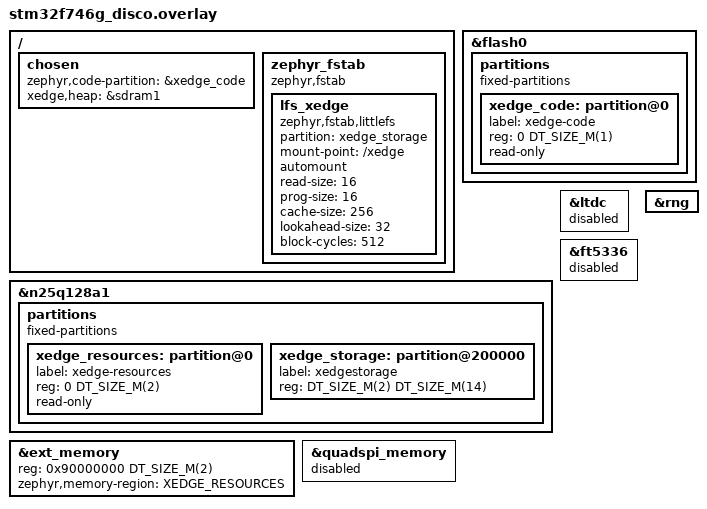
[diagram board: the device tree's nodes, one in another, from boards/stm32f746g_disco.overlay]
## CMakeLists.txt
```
cmake_minimum_required(VERSION 3.20.0)

# Find Zephyr package (this sets up the build system)
find_package(Zephyr REQUIRED HINTS $ENV{ZEPHYR_BASE})

project(XedgeInit)

# Application source files
target_sources(app PRIVATE src/main.c src/mdns.c)
include(${CMAKE_CURRENT_SOURCE_DIR}/../zephyr/Dns.cmake)

if(CONFIG_BOARD_FRDM_RW612 AND CONFIG_XEDGE_PSA)
  set_property(TARGET zephyr_property_target APPEND PROPERTY TFM_CMAKE_OPTIONS
    -DTFM_EXTRA_CONFIG_PATH=${CMAKE_CURRENT_SOURCE_DIR}/tfm/frdm_rw612/config.cmake)
  # Match the algorithms enabled by NXP's TF-M crypto configuration.
  zephyr_compile_definitions(
    SHARKSSL_USE_CHACHA20=0
    SHARKSSL_USE_POLY1305=0
    SHARKSSL_ECC_USE_BRAINPOOLP256R1=0
    SHARKSSL_ECC_USE_BRAINPOOLP384R1=0
    SHARKSSL_ECC_USE_BRAINPOOLP512R1=0
  )
endif()

if(CONFIG_FLASH_MCUX_FLEXSPI_XIP)
  # The controller addresses must remain readable while the XIP flash is busy.
  # Zephyr relocates this driver's code; also relocate its constant configuration.
  zephyr_code_relocate(
    FILES ${ZEPHYR_BASE}/drivers/memc/memc_mcux_flexspi.c
    LOCATION ${CONFIG_FLASH_MCUX_FLEXSPI_XIP_MEM}_RODATA
  )
endif()
```

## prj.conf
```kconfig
# Shared Xedge configuration. Hardware and simulator settings live in boards/.

# Enable Xedge module
CONFIG_XEDGE=y


# --- Sockets / contexts / FDs ---
# Each TCP connection consumes a net_context and a POSIX FD.
CONFIG_NET_MAX_CONTEXTS=32
CONFIG_NET_MAX_CONN=32
CONFIG_NET_SOCKETS_POLL_MAX=64

# --- Buffers (keep or increase from earlier tuning) ---
# Ensure pools don't starve when you scale connections.
CONFIG_NET_BUF_DATA_SIZE=512
CONFIG_NET_BUF_RX_COUNT=128
CONFIG_NET_BUF_TX_COUNT=128
CONFIG_NET_PKT_RX_COUNT=128
CONFIG_NET_PKT_TX_COUNT=128

# Bound each connection's window so concurrent IDE asset downloads share pools.
CONFIG_NET_TCP_MAX_SEND_WINDOW_SIZE=4096
CONFIG_NET_TCP_MAX_RECV_WINDOW_SIZE=4096

# --- Debug aids (temporarily) ---
CONFIG_LOG=y
CONFIG_LOG_DEFAULT_LEVEL=3
CONFIG_NET_LOG=y
CONFIG_NET_STATISTICS=y
CONFIG_NET_STATISTICS_USER_API=y


# Networking - Essential for HTTP server
CONFIG_NETWORKING=y
CONFIG_NET_IPV4=y
CONFIG_NET_IPV6=y
CONFIG_NET_TCP=y
CONFIG_NET_UDP=y
CONFIG_NET_SOCKETS=y
CONFIG_SNTP=y

# DNS resolver; each board selects static or DHCP-provided servers.
CONFIG_DNS_RESOLVER=y
# Keep the multicast entries added after DHCP initializes unicast DNS.
CONFIG_DNS_RECONFIGURE_CLEANUP=n
# Helpful if some domains have big/long answers
CONFIG_DNS_RESOLVER_ADDITIONAL_BUF_CTR=3
CONFIG_DNS_NUM_CONCUR_QUERIES=3
# Process DNS replies before the Xedge TLS workers (base priority 5).
# The default socket-service priority can starve until DNS queries time out.
CONFIG_NET_SOCKETS_SERVICE_THREAD_PRIO=2
# Native mDNS runs in this thread and needs more than the default 1400 bytes.
CONFIG_NET_SOCKETS_SERVICE_STACK_SIZE=4096

# Native mDNS on every target, including Lua-selected SharkCA hostnames.
CONFIG_MDNS_RESPONDER=y
CONFIG_MDNS_RESOLVER=y
CONFIG_NET_HOSTNAME_ENABLE=y
CONFIG_NET_HOSTNAME_DYNAMIC=y
CONFIG_NET_HOSTNAME_MAX_LEN=63
CONFIG_NET_HOSTNAME="xedge"
CONFIG_NET_HOSTNAME_UNIQUE=y

# Initialize the board's network interface before starting Xedge.
CONFIG_NET_CONFIG_AUTO_INIT=y
CONFIG_NET_CONFIG_SETTINGS=y
CONFIG_NET_CONFIG_NEED_IPV4=y


# Threading and scheduling
CONFIG_MULTITHREADING=y
CONFIG_NUM_PREEMPT_PRIORITIES=16
CONFIG_NUM_COOP_PRIORITIES=16
CONFIG_MAIN_STACK_SIZE=2048
CONFIG_IDLE_STACK_SIZE=2048
CONFIG_SYSTEM_WORKQUEUE_STACK_SIZE=4096

# Memory management
CONFIG_HEAP_MEM_POOL_SIZE=61440
CONFIG_DYNAMIC_THREAD=y

# Console and shell
CONFIG_CONSOLE=y
CONFIG_UART_CONSOLE=y
CONFIG_SHELL=y
CONFIG_SHELL_BACKEND_SERIAL=y
CONFIG_SHELL_STACK_SIZE=4096

# POSIX API (helps with BAS porting layer)
CONFIG_POSIX_API=y
CONFIG_ZVFS_OPEN_MAX=64

CONFIG_EVENTFD=y

# Entropy (required for network randomization)
CONFIG_ENTROPY_GENERATOR=y

# Disable assertions for cleaner output
#CONFIG_ASSERT=y
#CONFIG_ASSERT_LEVEL=0

# Increase various limits for BAS
CONFIG_MAIN_THREAD_PRIORITY=5

# GPIO (optional - for LED examples)
CONFIG_GPIO=y

# File system support
# Zephyr VFS + LittleFS; each board supplies its flash partition and mount.
CONFIG_FILE_SYSTEM=y
CONFIG_FILE_SYSTEM_LITTLEFS=y
CONFIG_FLASH=y
CONFIG_FLASH_MAP=y
```

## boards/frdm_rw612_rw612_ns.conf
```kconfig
# FRDM-RW612: Ethernet and DHCP, with the TPM provided by secure TF-M firmware.
CONFIG_NET_L2_ETHERNET=y
CONFIG_NET_DHCPV4=y
CONFIG_DNS_SERVER_IP_ADDRESSES=n
CONFIG_NET_DHCPV4_OPTION_DNS_ADDRESS=y
CONFIG_TEST_RANDOM_GENERATOR=n
CONFIG_BUILD_WITH_TFM=y
# Let the TF-M dispatcher keep the calling thread scheduled until PSA returns.
# Interrupts remain enabled; a suspended secure crypto call must not be switched
# away from by the nonsecure scheduler on this platform.
CONFIG_ARM_NONSECURE_PREEMPTIBLE_SECURE_CALLS=n
CONFIG_TFM_PARTITION_CRYPTO=y
CONFIG_TFM_PARTITION_INTERNAL_TRUSTED_STORAGE=y
CONFIG_XEDGE_PSA=y
CONFIG_USE_DT_CODE_PARTITION=y

# Keep 70% of the 8 MiB PSRAM for Xedge, rounded down to 8 bytes.
# Zephyr's data, network pools, and all thread stacks stay in internal SRAM.
CONFIG_XEDGE_HEAP_SIZE=5872024
CONFIG_HEAP_MEM_POOL_SIZE=262144
CONFIG_MEM_ATTR=y
CONFIG_MEMC=y

# NXP's nonsecure PSRAM sample requires this flash-before-PSRAM init order.
CONFIG_MEMC_MCUX_FLEXSPI_INIT_PRIORITY=0
CONFIG_FLASH_INIT_PRIORITY=50
CONFIG_MEMC_INIT_PRIORITY=60
CONFIG_MEMC_MCUX_FLEXSPI_INIT_XIP=y
CONFIG_FLASH_LOG_LEVEL_OFF=y
CONFIG_MEMC_LOG_LEVEL_OFF=y
CONFIG_FS_LITTLEFS_CACHE_SIZE=256

# Keep assertions enabled for board bring-up.
CONFIG_ASSERT=y
```

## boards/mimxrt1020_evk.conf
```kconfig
# MIMXRT1020-EVK: wired Ethernet with DHCP-provided address and DNS servers.
CONFIG_NET_L2_ETHERNET=y
CONFIG_NET_DHCPV4=y
CONFIG_DNS_SERVER_IP_ADDRESSES=n
CONFIG_NET_DHCPV4_OPTION_DNS_ADDRESS=y

# Reserve 70% of 32 MiB SDRAM for Xedge, rounded down to 8 bytes.
CONFIG_XEDGE_HEAP_SIZE=23488096
# Leave room for initialization and SNTP calls on the main thread.
CONFIG_MAIN_STACK_SIZE=4096
CONFIG_TEST_RANDOM_GENERATOR=n

# Match the overlay's per-file cache size.
CONFIG_FS_LITTLEFS_CACHE_SIZE=256

# Boot directly from QSPI; keep writable files outside the firmware image.
CONFIG_XIP=y
CONFIG_USE_DT_CODE_PARTITION=y
CONFIG_MPU_ALLOW_FLASH_WRITE=y

# The FlexSPI XIP driver runs flash operations from RAM.
CONFIG_FLASH_LOG_LEVEL_OFF=y
CONFIG_MEMC_LOG_LEVEL_OFF=y
```

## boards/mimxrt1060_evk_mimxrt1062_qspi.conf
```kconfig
# MIMXRT1060-EVKC: use the board's Ethernet PHY and DHCP on the local LAN.
CONFIG_NET_L2_ETHERNET=y
CONFIG_NET_DHCPV4=y
CONFIG_DNS_SERVER_IP_ADDRESSES=n
CONFIG_NET_DHCPV4_OPTION_DNS_ADDRESS=y

# Reserve 70% of this board's 32 MiB SDRAM for Xedge, rounded down to 8 bytes:
# floor((32 * 1024 * 1024 * 70 / 100) / 8) * 8 = 23488096 bytes (22.4 MiB).
# Zephyr stacks, network buffers, and other data use part of the remaining 30%.
CONFIG_XEDGE_HEAP_SIZE=23488096

# Match the overlay so the file-cache heap supports all configured open files.
CONFIG_FS_LITTLEFS_CACHE_SIZE=256

# Run directly from QSPI flash. Bound the image to its devicetree partition.
CONFIG_XIP=y
CONFIG_USE_DT_CODE_PARTITION=y
CONFIG_MPU_ALLOW_FLASH_WRITE=y

# Zephyr selects FLASH_MCUX_FLEXSPI_XIP and relocates the flash path to RAM.
CONFIG_FLASH_LOG_LEVEL_OFF=y
CONFIG_MEMC_LOG_LEVEL_OFF=y

# Use the MCU entropy driver; never enable the simulator test RNG here.
CONFIG_TEST_RANDOM_GENERATOR=n
```

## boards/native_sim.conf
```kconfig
# Board-specific configuration for native_sim
# This file is automatically included when building for native_sim

# Networking for native_sim
CONFIG_NET_NATIVE=y

# Preserve the existing TAP network and simulator test settings.
CONFIG_NET_CONFIG_MY_IPV4_ADDR="10.200.200.2"
CONFIG_NET_CONFIG_PEER_IPV4_ADDR="10.200.200.1"
CONFIG_NET_CONFIG_MY_IPV4_GW="10.200.200.1"
CONFIG_DNS_SERVER_IP_ADDRESSES=y
CONFIG_DNS_SERVER1="8.8.8.8"
CONFIG_NET_TCP_TIME_WAIT_DELAY=2000
CONFIG_TEST_RANDOM_GENERATOR=y

# Persistent simulated flash, also exposed through the host FUSE mount.
CONFIG_FLASH_SIMULATOR=y
CONFIG_FUSE_FS_ACCESS=y
```

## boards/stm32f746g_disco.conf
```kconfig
# STM32F746G-DISCO: Ethernet with DHCP-provided address and DNS servers.
CONFIG_NET_L2_ETHERNET=y
CONFIG_NET_DHCPV4=y
CONFIG_DNS_SERVER_IP_ADDRESSES=n
CONFIG_NET_DHCPV4_OPTION_DNS_ADDRESS=y

# ACME plus concurrent TLS connections exhausted the default 2 MiB heap.
# Reserve 70% of 8 MiB SDRAM, rounded down to an 8-byte boundary.
CONFIG_XEDGE_HEAP_SIZE=5872024
# Initialize external SDRAM before main() uses the Xedge heap.
# Kernel data and Ethernet DMA buffers stay in internal SRAM.
CONFIG_MEMC=y
CONFIG_TEST_RANDOM_GENERATOR=n
# Startup and SNTP used 1,928 bytes on hardware; retain room for call variation.
CONFIG_MAIN_STACK_SIZE=4096

# Keep the network pools within 256 KiB SRAM. Xedge allocations use SDRAM.
# Each direction retains 32 KiB of packet data and 4 KiB TCP windows.
CONFIG_NET_BUF_RX_COUNT=64
CONFIG_NET_BUF_TX_COUNT=64
CONFIG_NET_PKT_RX_COUNT=64
CONFIG_NET_PKT_TX_COUNT=64
CONFIG_HEAP_MEM_POOL_SIZE=32768

# Match the overlay so the file-cache heap supports all configured open files.
CONFIG_FS_LITTLEFS_CACHE_SIZE=256

# Boot from internal flash; store the resource ZIP and LittleFS in QSPI.
CONFIG_XIP=y
CONFIG_USE_DT_CODE_PARTITION=y
CONFIG_XEDGE_RESOURCE_FLASH=y
# HEX/ELF represent the separate internal and external flash addresses.
# A flat binary would include the approximately 2 GiB address gap.
CONFIG_BUILD_OUTPUT_BIN=n
CONFIG_BUILD_OUTPUT_HEX=y
```

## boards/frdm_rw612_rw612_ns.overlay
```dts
/*
 * PSRAM pin and RX-buffer configuration follows NXP's memc sample.
 * Copyright 2026 NXP
 * Copyright 2026 Real Time Logic
 * SPDX-License-Identifier: Apache-2.0
 */
#include <zephyr/dt-bindings/memory-attr/memory-attr-arm.h>
#include "frdm_rw612_memory.h"

/ {
    chosen {
        xedge,heap = &xedge_psram;
    };

    xedge_psram: memory@c000000 {
        compatible = "zephyr,memory-region";
        reg = <0x0c000000 DT_SIZE_M(8)>;
        zephyr,memory-region = "XEDGE_PSRAM";
        zephyr,memory-region-flags = "rw";
        zephyr,memory-attr = <DT_MEM_ARM_MPU_RAM>;
    };

    zephyr_fstab {
        compatible = "zephyr,fstab";
        lfs_xedge: lfs_xedge {
            compatible = "zephyr,fstab,littlefs";
            partition = <&xedge_storage>;
            mount-point = "/xedge";
            automount;
            read-size = <16>;
            prog-size = <16>;
            cache-size = <256>;
            lookahead-size = <32>;
            block-cycles = <512>;
        };
    };
};

&w25q512jvfiq {
    partitions {
        xedge_storage: partition@1000000 {
            label = "xedgestorage";
            reg = <XEDGE_STORAGE_OFFSET XEDGE_STORAGE_SIZE>;
        };
    };
};

&ext_flash_ctrl {
    spi-max-frequency = <109000000>;
};

&aps6404l {
    status = "okay";
};

&pinctrl {
    pinmux_flexspi_safe: pinmux-flexspi-safe {
        group0 {
            pinmux = <IO_MUX_QUAD_SPI_PSRAM_IO35
                      IO_MUX_QUAD_SPI_PSRAM_IO36
                      IO_MUX_QUAD_SPI_PSRAM_IO38
                      IO_MUX_QUAD_SPI_PSRAM_IO39
                      IO_MUX_QUAD_SPI_PSRAM_IO40
                      IO_MUX_QUAD_SPI_PSRAM_IO41>;
            slew-rate = "normal";
        };
        group1 {
            pinmux = <IO_MUX_QUAD_SPI_PSRAM_IO37>;
            slew-rate = "normal";
            bias-pull-down;
        };
    };
};

&flexspi {
    pinctrl-0 = <&pinmux_flexspi_safe>;
    pinctrl-names = "default";
    rx-buffer-config = <1 0 10 512>, <0 0 0 0>, <0 0 0 0>, <0 0 0 0>,
                       <0 0 0 0>, <0 0 0 0>, <0 0 0 0>, <1 0 0 512>;
};
```

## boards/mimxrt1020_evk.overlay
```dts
/ {
    chosen {
        zephyr,code-partition = &xedge_code;
    };

    zephyr_fstab {
        compatible = "zephyr,fstab";
        lfs_xedge: lfs_xedge {
            compatible = "zephyr,fstab,littlefs";
            partition = <&xedge_storage>;
            mount-point = "/xedge";
            automount;
            read-size = <16>;
            prog-size = <16>;
            cache-size = <256>;
            lookahead-size = <32>;
            block-cycles = <512>;
        };
    };
};

&is25lp064 {
    /delete-node/ partitions;
    partitions {
        compatible = "fixed-partitions";
        #address-cells = <1>;
        #size-cells = <1>;

        /* ROM-bootable firmware, including the NXP boot header. */
        xedge_code: partition@0 {
            label = "xedge-code";
            reg = <0x00000000 0x00400000>;
            read-only;
        };

        /* Preserve this partition when updating firmware. */
        xedge_storage: partition@400000 {
            label = "xedgestorage";
            reg = <0x00400000 0x00400000>;
        };
    };
};

/* Keep the Ethernet identity stable across reboots for DHCP and DNS. */
&enet_mac {
    /delete-property/ zephyr,random-mac-address;
    nxp,unique-mac;
};

/* Use the PHY driver's periodic link monitor. */
&phy {
	/delete-property/ int-gpios;
};
```

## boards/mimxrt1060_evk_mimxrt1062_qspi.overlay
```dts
/* Revision C has a 16 MiB W25Q128JW. This deliberately requires EVKC. */
/ {
    chosen {
        zephyr,code-partition = &xedge_code;
    };

    zephyr_fstab {
        compatible = "zephyr,fstab";
        lfs_xedge: lfs_xedge {
            compatible = "zephyr,fstab,littlefs";
            partition = <&xedge_storage>;
            mount-point = "/xedge";
            automount;
            read-size = <16>;
            prog-size = <16>;
            cache-size = <256>;
            lookahead-size = <32>;
            block-cycles = <512>;
        };
    };
};

&w25q128jw {
    /delete-node/ partitions;
    partitions {
        compatible = "fixed-partitions";
        #address-cells = <1>;
        #size-cells = <1>;

        /* Standalone ROM-bootable image, including the NXP boot header. */
        xedge_code: partition@0 {
            label = "xedge-code";
            reg = <0x00000000 0x00400000>;
            read-only;
        };

        /* Firmware updates must preserve this separate 12 MiB filesystem. */
        xedge_storage: partition@400000 {
            label = "xedgestorage";
            reg = <0x00400000 0x00c00000>;
        };
    };
};
```

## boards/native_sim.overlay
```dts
/ {
    /* Ensure simulated flash is the default flash device */
    chosen {
        zephyr,flash = &flash0;
    };

    /* Create zephyr_fstab and add a LittleFS entry that mounts at /xedge */
    zephyr_fstab: zephyr_fstab {
        compatible = "zephyr,fstab";

        lfs_xedge: lfs_xedge {
            compatible  = "zephyr,fstab,littlefs";
            partition   = <&lfs0>;
            mount-point = "/xedge";
            automount;

            /* Reasonable defaults for native_sim */
            read-size      = <16>;
            prog-size      = <16>;
            cache-size     = <64>;
            lookahead-size = <32>;
            block-cycles = <512>;
        };
    };
};

/* Define a partition on the simulated flash and label it 'lfs0' */
&flash0 {
    partitions {
        compatible = "fixed-partitions";
        #address-cells = <1>;
        #size-cells    = <1>;

        /* 1 MiB for LittleFS (tune as needed) */
        lfs0: partition@0 {
            label = "xedgestorage";
            reg = <0x00000000 0x00100000>;
        };
    };
};
```

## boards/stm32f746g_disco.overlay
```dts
/ {
    chosen {
        zephyr,code-partition = &xedge_code;
        xedge,heap = &sdram1;
    };

    zephyr_fstab {
        compatible = "zephyr,fstab";
        lfs_xedge: lfs_xedge {
            compatible = "zephyr,fstab,littlefs";
            partition = <&xedge_storage>;
            mount-point = "/xedge";
            automount;
            read-size = <16>;
            prog-size = <16>;
            cache-size = <256>;
            lookahead-size = <32>;
            block-cycles = <512>;
        };
    };
};

&flash0 {
    #address-cells = <1>;
    #size-cells = <1>;
    ranges = <0 0x08000000 DT_SIZE_M(1)>;
    /delete-node/ partitions;
    partitions {
        compatible = "fixed-partitions";
        #address-cells = <1>;
        #size-cells = <1>;
        ranges;
        xedge_code: partition@0 {
            label = "xedge-code";
            reg = <0 DT_SIZE_M(1)>;
            read-only;
        };
    };
};

&n25q128a1 {
    /delete-node/ partitions;
    partitions {
        compatible = "fixed-partitions";
        #address-cells = <1>;
        #size-cells = <1>;
        /* Program the resource ZIP separately from writable application data. */
        xedge_resources: partition@0 {
            label = "xedge-resources";
            reg = <0 DT_SIZE_M(2)>;
            read-only;
        };

        xedge_storage: partition@200000 {
            label = "xedgestorage";
            reg = <DT_SIZE_M(2) DT_SIZE_M(14)>;
        };
    };
};

/* Link the ZIP at its programming address; runtime reads use flash_area_read. */
&ext_memory {
    reg = <0x90000000 DT_SIZE_M(2)>;
    zephyr,memory-region = "XEDGE_RESOURCES";
};

/* The board already describes the external flash region above. */
&quadspi_memory {
    status = "disabled";
};

/* The browser is the demo's UI; leave SDRAM available for Xedge. */
&ltdc {
    status = "disabled";
};

&ft5336 {
    status = "disabled";
};

/* Seed SharkSSL and Zephyr networking from the hardware RNG. */
&rng {
    status = "okay";
};
```

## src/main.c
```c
/*
 * Copyright (c) 2025 - 2026 Real Time Logic
 * Xedge (xedge.c) and Barracuda App Server (BAS) initialization and startup code for the Zephyr RTOS
 * Targets: native_sim, NXP i.MX RT, FRDM-RW612, and STM32F746G-DISCO
 */
#include <zephyr/kernel.h>
#include <zephyr/sys/printk.h>
#include <zephyr/logging/log.h>
#include <zephyr/net/sntp.h>
#include <zephyr/net/net_mgmt.h>
#include <zephyr/net/net_event.h>
#include <zephyr/drivers/entropy.h>
#include <zephyr/linker/devicetree_regions.h>

// BAS includes
#include <TargConfig.h>
#include <barracuda.h>
#include <HttpTrace.h>
#include <HttpServer.h>
#include <BaErrorCodes.h>
#include <xedge.h>
#include "mdns.h"

// From Xedge (xedge.c) - the main server loop.
extern void barracuda(void);
/* The LThreadMgr configured in xedge.c */
extern LThreadMgr ltMgr;

LOG_MODULE_REGISTER(xedge_main, LOG_LEVEL_INF);

/* xedgeOpenAUX runs after the Lua thread manager has been constructed. */
K_SEM_DEFINE(xedge_ready, 0, 1);

#if SHARKSSL_PSA_CONSUMER
#include <psa/crypto.h>

/* TF-M has initialized its secure storage before entering Zephyr. Xedge calls
 * this hook before resource verification and Lua TPM initialization.
 */
int xedgeInitPsa(void)
{
   return (int)psa_crypto_init();
}
#endif

// dlmalloc initialization. Enabled by default.
#if BA_ALLOCATOR == BA_ALLOCATOR_DLMALLOC
#include <dlmalloc.h>

static void dlmalloc_exhausted_handler(void)
{
    LOG_ERR("DLMALLOC EXHAUSTED - Out of heap memory!");
    printk("CRITICAL: dlmalloc heap exhausted!\n");
}
#endif


/* Thread stack for Xedge main server loop and all BAS threads
   Inherits CONFIG_XEDGE_STACK_SIZE from prj.conf and set in
   CMakeLists.txt
 */
K_THREAD_STACK_DEFINE(xedge_stack, BA_THREAD_STACK_SIZE);
struct k_thread xedge_thread_data;

/**
 * Trace callback for HTTP tracing
 * This is called by BAS to output diagnostic messages
 */
static void xedge_trace_callback(char* buf, int bufLen)
{
   if(bufLen > 0)
   {
      if(buf[bufLen-1] == '\n')
         buf[bufLen-1] = 0;
      else
         buf[bufLen] = 0; // Null terminate
      LOG_INF("%s", buf);
   }
}

/**
 * Fatal error handler for Barracuda
 * Called when BAS encounters an unrecoverable error
 */
static void xedge_error_handler(BaFatalErrorCodes ecode1, 
                                unsigned int ecode2, 
                                const char* file, 
                                int line)
{
    LOG_ERR("Barracuda Fatal Error: %d %d at %s:%d", 
            ecode1, ecode2, file, line);
    printk("FATAL: Barracuda error %d %d at %s:%d\n", 
           ecode1, ecode2, file, line);
    k_panic();
}

/**
 * Xedge disk I/O initialization (optional)
 * Return -1 to use NetIo instead of DiskIo
 */
#if XEDGE_ENABLE_DISK_IO
int xedgeInitDiskIo(DiskIo* dio)
{
   LOG_INF("main.c - xedgeInitDiskIo: Mounting /xedge");
   if(DiskIo_setRootDir(dio,"/xedge"))
   {
      LOG_ERR("Cannot mount /xedge; see readme for details");
      k_panic();
   }
   return 0;
}
#endif

/*
  The function below is called by the Xedge startup code.
  This is a good place to add your own Lua bindings.
  See example code in BAS/examples/xedge/src led.c and AsynchLua.c
*/
int xedgeOpenAUX(XedgeOpenAUX* aux)
{
   xedgeMdnsInit(aux->L);
   k_sem_give(&xedge_ready);
   return 0; /* OK */
}


/**
 * Xedge server thread
 * This thread runs the Barracuda server (never returns)
 */
static void xedge_server_thread(void *arg1, void *arg2, void *arg3)
{
    ARG_UNUSED(arg1);
    ARG_UNUSED(arg2);
    ARG_UNUSED(arg3);

    LOG_INF("Starting the Xedge main loop");
    barracuda();
    // Above should not return
    LOG_ERR("barracuda() returned unexpectedly!");
}


/* We wait for the time to be set in function main(). When the time is
   set, main() triggers this function, which calls the Lua
   '_XedgeEvent' function with the argument sntp to signal that we
   have the correct time.

   This callback is called by one of the threads managed by LThreadMgr
   when a job is taken off the queue and executed. The callback
   attempts to find the global Lua function '_XedgeEvent', and if the
   function is found, it will be executed as follows:
   _XedgeEvent("sntp")

   The LThreadMgr object:
   https://realtimelogic.com/ba/doc/en/C/reference/html/md_en_C_md_LuaBindings.html#fullsolution
   Why time is important:
   https://realtimelogic.com/ba/examples/xedge/readme.html#time
*/
static void sntp_event(ThreadJob* job, int msgh, LThreadMgr* mgr)
{
   lua_State* L = job->Lt;
   lua_pushglobaltable(L); /* _G */
   lua_getfield(L, -1, "_XedgeEvent");
   if(lua_isfunction(L, -1))  /* Do we have _G._XedgeEvent */
   {
      /* Call _XedgeEvent("sntp") */
      lua_pushstring(L,"sntp"); /* Arg */
      lua_pcall(L, 1, 0, msgh); /* one arg, no return value */
   }
}



/**
 * Main application entry point
 */
int main(void)
{
    LOG_INF("Xedge application starting...");
    LOG_INF("Board: %s", CONFIG_BOARD);
    LOG_INF("Xedge stack size: %d bytes", BA_THREAD_STACK_SIZE);
#if BA_ALLOCATOR == BA_ALLOCATOR_DLMALLOC
    // Initialize dlmalloc heap
    /* Optional external heap is NOLOAD: SDRAM is initialized after BSS. */
    static char heap_pool[CONFIG_XEDGE_HEAP_SIZE] __aligned(8)
#if DT_HAS_CHOSEN(xedge_heap)
        Z_GENERIC_SECTION(LINKER_DT_NODE_REGION_NAME(DT_CHOSEN(xedge_heap)))
#endif
        ;
#if DT_HAS_CHOSEN(xedge_heap)
    BUILD_ASSERT(CONFIG_XEDGE_HEAP_SIZE <= DT_REG_SIZE(DT_CHOSEN(xedge_heap)),
                 "Xedge heap exceeds its memory region");
#endif
#if defined(CONFIG_BOARD_STM32F746G_DISCO)
    if (!device_is_ready(DEVICE_DT_GET(DT_CHILD(DT_NODELABEL(fmc), sdram))))
    {
        LOG_ERR("Cannot initialize SDRAM for the Xedge heap");
        k_panic();
    }
#endif
#if defined(CONFIG_BOARD_FRDM_RW612)
    if (!device_is_ready(DEVICE_DT_GET(DT_NODELABEL(aps6404l))))
    {
        LOG_ERR("Cannot initialize PSRAM for the Xedge heap");
        k_panic();
    }
#endif
    init_dlmalloc(heap_pool, heap_pool + sizeof(heap_pool));
    dlmalloc_setExhaustedCB(dlmalloc_exhausted_handler);
    LOG_INF("Xedge - dlmalloc initialized - heap size: %d bytes", sizeof(heap_pool));
#endif
    /* Initialize cryptography before TLS or key-generation work starts. */
#if defined(CONFIG_XEDGE_PSA)
    if (sharkssl_entropy() != 0)
    {
        LOG_ERR("Cannot initialize PSA cryptography");
        k_panic();
    }
#else
    const struct device *entropy = DEVICE_DT_GET(DT_CHOSEN(zephyr_entropy));
    uint8_t seed[48];
    if (!device_is_ready(entropy) ||
        entropy_get_entropy(entropy, (uint8_t *)seed, sizeof(seed)) != 0)
    {
        LOG_ERR("Cannot obtain startup entropy");
        k_panic();
    }
    int seeded = sharkssl_entropyEx(seed, sizeof(seed));
    memset(seed, 0, sizeof(seed));
    if (seeded != 0)
    {
        LOG_ERR("Cannot seed SharkSSL");
        k_panic();
    }
#endif

    // Set up error handler and trace callback
    HttpServer_setErrHnd(xedge_error_handler);
    HttpTrace_setFLushCallback(xedge_trace_callback);

    k_thread_create(&xedge_thread_data, xedge_stack,
                    K_THREAD_STACK_SIZEOF(xedge_stack),
                    xedge_server_thread, NULL, NULL, NULL,
                    CONFIG_XEDGE_THREAD_PRIORITY, 0, K_NO_WAIT);

    /* A fast SNTP response must not access an uninitialized ltMgr. */
    k_sem_take(&xedge_ready, K_FOREVER);

    for(;;)
    {
       struct sntp_time sntp_time;
       int ret = sntp_simple("pool.ntp.org", 5000, &sntp_time);
       if (ret == 0)
       {
          struct timespec ts = {
             .tv_sec = sntp_time.seconds,
             .tv_nsec = 0
          };
          clock_settime(CLOCK_REALTIME, &ts);
          /* Initiate executing the Lua func _XedgeEvent("sntp") */
          ThreadJob* job=ThreadJob_lcreate(sizeof(ThreadJob), sntp_event);
          if (!job)
          {
             LOG_ERR("Cannot allocate the SNTP notification");
             k_panic();
          }
          ThreadMutex* soDispMutex = HttpServer_getMutex(ltMgr.server);
          ThreadMutex_set(soDispMutex);
          LThreadMgr_run(&ltMgr, job);
          ThreadMutex_release(soDispMutex);
          break;
       }
       else
       {
          LOG_ERR("NTP sync failed: %s (%d). Did you configure your network?",
                  zsock_gai_strerror(ret), ret);
          k_sleep(K_SECONDS(2));
       }
    }
    
    // Main thread continues - could do other work here
    for(;;)
    {
       k_sleep(K_SECONDS(30));
       LOG_INF("Uptime: %lld seconds", k_uptime_get() / 1000);
    }

    return 0;
}
```

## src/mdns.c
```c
/* Copyright (c) 2026 Real Time Logic
 * Lua ownership of Zephyr's single native mDNS hostname.
 */
#include <zephyr/net/hostname.h>
#include <zephyr/net/dns_resolve.h>
#include <zephyr/logging/log.h>
#include <lauxlib.h>
#include <string.h>
#include "mdns.h"

LOG_MODULE_REGISTER(xedge_mdns, LOG_LEVEL_INF);

#if !defined(CONFIG_MDNS_RESPONDER) || !defined(CONFIG_NET_HOSTNAME_DYNAMIC)
#error Xedge requires Zephyr native mDNS and dynamic hostname support
#endif

#define MDNS_META "Xedge.Zephyr.mDNS"

typedef struct
{
   char name[NET_HOSTNAME_SIZE];
   char previous[NET_HOSTNAME_SIZE];
} XedgeMdns;

/* Lua owns the userdata. All accesses run under the BAS dispatcher mutex;
 * close/GC clears this non-owning pointer before the userdata is released.
 */
static XedgeMdns* active;

static int mdnsError(lua_State* L, const char* message)
{
   lua_pushnil(L);
   lua_pushstring(L,message);
   return 2;
}

static int mdnsClose(lua_State* L)
{
   XedgeMdns* o=luaL_checkudata(L,1,MDNS_META);
   if(active == o)
   {
      /* Do not undo a hostname change made elsewhere in the application. */
      if(!strcmp(net_hostname_get(),o->name))
         net_hostname_set(o->previous,strlen(o->previous));
      active=NULL;
   }
   return 0;
}

static int mdnsStatus(lua_State* L)
{
   XedgeMdns* o=luaL_checkudata(L,1,MDNS_META);
   if(active != o)
      return mdnsError(L,"closed");
   if(strcmp(net_hostname_get(),o->name))
      return mdnsError(L,"hostname changed");
   lua_pushboolean(L,1);
   return 1;
}

static int mdnsCreate(lua_State* L)
{
   XedgeMdns* o;
   size_t len;
   const char* name;

   luaL_checktype(L,1,LUA_TSTRING);
   name=lua_tolstring(L,1,&len);
   luaL_argcheck(L,len == strlen(name),1,"name contains NUL");
   if(!len || len > 63 || len > NET_HOSTNAME_MAX_LEN ||
      name[0] == '-' || name[len-1] == '-')
      return mdnsError(L,"invalid name");
   for(size_t i=0; i<len; ++i)
   {
      unsigned char c=(unsigned char)name[i];
      if(!((c >= 'a' && c <= 'z') || (c >= 'A' && c <= 'Z') ||
           (c >= '0' && c <= '9') || c == '-'))
         return mdnsError(L,"invalid name");
   }
   if(active)
      return mdnsError(L,"mDNS hostname already in use");

   /* Allocate and attach the finalizer before changing native state. */
   o=lua_newuserdatauv(L,sizeof(*o),0);
   luaL_setmetatable(L,MDNS_META);
   memcpy(o->name,name,len);
   o->name[len]=0;
   strcpy(o->previous,net_hostname_get());
   if(net_hostname_set(o->name,len))
      return mdnsError(L,"cannot set hostname");
   active=o;
   return 1;
}

void xedgeMdnsInit(lua_State* L)
{
   static const char* servers[] = {
#if defined(CONFIG_NET_IPV4)
      "224.0.0.251:5353",
#endif
#if defined(CONFIG_NET_IPV6)
      "[ff02::fb]:5353",
#endif
      NULL
   };
   static const luaL_Reg methods[] = {
      {"status",mdnsStatus},
      {"close",mdnsClose},
      {"__close",mdnsClose},
      {"__gc",mdnsClose},
      {NULL,NULL}
   };
   /* Network setup has completed before Xedge starts. Append multicast DNS
    * after DHCP's unicast server: Zephyr tries the first eligible server.
    * Static configurations already containing these entries are unchanged.
    */
   int err=dns_resolve_reconfigure(dns_resolve_get_default(),servers,NULL,
                                   DNS_SOURCE_MANUAL);
   if(err)
      LOG_ERR("Cannot initialize mDNS resolver (%d)",err);
   if(luaL_newmetatable(L,MDNS_META))
   {
      lua_pushvalue(L,-1);
      lua_setfield(L,-2,"__index");
      luaL_setfuncs(L,methods,0);
   }
   lua_pop(L,1);
   lua_getglobal(L,"ba");
   lua_pushcfunction(L,mdnsCreate);
   lua_setfield(L,-2,"createmdns");
   lua_pop(L,1);
}
```

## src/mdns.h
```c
/* Copyright (c) 2026 Real Time Logic */
#ifndef XEDGE_ZEPHYR_MDNS_H
#define XEDGE_ZEPHYR_MDNS_H

#include <lua.h>

/* Install ba.createmdns; called with the BAS dispatcher mutex held.
 * Leaves the Lua stack unchanged.
 */
void xedgeMdnsInit(lua_State* L);

#endif
```
